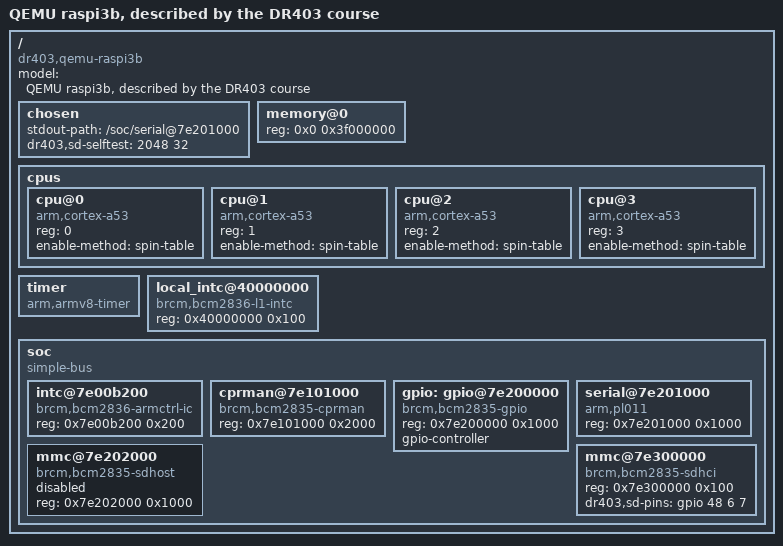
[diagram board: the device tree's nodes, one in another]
// raspi3b.dts - DR403: a devicetree for QEMU 8.2.2's raspi3b machine, written for this course.
//
// It is NOT the vendor's devicetree. Every address below was read from QEMU's own memory-tree
// listing of that machine in this build (run.sh step "mtree"): the peripherals answer at
// 0x7e...... in the VideoCore bus view and at 0x3f...... in the CPU view, so the soc node
// translates one to the other with "ranges". Compatible strings for Arm parts ("arm,pl011",
// "arm,armv8-timer") are the ones QEMU itself writes into its virt devicetree; the "brcm,..."
// strings follow the names used by Linux bindings and are NOT verified in this build.
// "dr403,..." strings are this course's own.
/ {
    model = "QEMU raspi3b, described by the DR403 course";
    compatible = "dr403,qemu-raspi3b";
    #address-cells = <1>;
    #size-cells = <1>;

    chosen {
        stdout-path = "/soc/serial@7e201000";
        dr403,sd-selftest = <2048 32>;     // scratch area: first block, number of test writes
    };

    memory@0 {
        device_type = "memory";
        reg = <0x0 0x3f000000>;
    };

    cpus {
        #address-cells = <1>;
        #size-cells = <0>;
        cpu@0 { device_type = "cpu"; compatible = "arm,cortex-a53"; reg = <0>; enable-method = "spin-table"; };
        cpu@1 { device_type = "cpu"; compatible = "arm,cortex-a53"; reg = <1>; enable-method = "spin-table"; };
        cpu@2 { device_type = "cpu"; compatible = "arm,cortex-a53"; reg = <2>; enable-method = "spin-table"; };
        cpu@3 { device_type = "cpu"; compatible = "arm,cortex-a53"; reg = <3>; enable-method = "spin-table"; };
    };

    timer {
        compatible = "arm,armv8-timer";
    };

    local_intc@40000000 {
        compatible = "brcm,bcm2836-l1-intc";
        reg = <0x40000000 0x100>;
    };

    soc {
        compatible = "simple-bus";
        #address-cells = <1>;
        #size-cells = <1>;
        ranges = <0x7e000000 0x3f000000 0x01000000>;

        intc@7e00b200 {
            compatible = "brcm,bcm2836-armctrl-ic";
            reg = <0x7e00b200 0x200>;
        };
        cprman@7e101000 {
            compatible = "brcm,bcm2835-cprman";
            reg = <0x7e101000 0x2000>;
        };
        gpio: gpio@7e200000 {
            compatible = "brcm,bcm2835-gpio";
            reg = <0x7e200000 0x1000>;
            gpio-controller;
            #gpio-cells = <2>;
        };
        serial@7e201000 {
            compatible = "arm,pl011", "arm,primecell";
            reg = <0x7e201000 0x1000>;
        };
        mmc@7e202000 {
            compatible = "brcm,bcm2835-sdhost";
            reg = <0x7e202000 0x1000>;
            status = "disabled";
        };
        mmc@7e300000 {
            compatible = "brcm,bcm2835-sdhci";
            reg = <0x7e300000 0x100>;
            dr403,sd-pins = <&gpio 48 6 7>;
        };
    };
};
